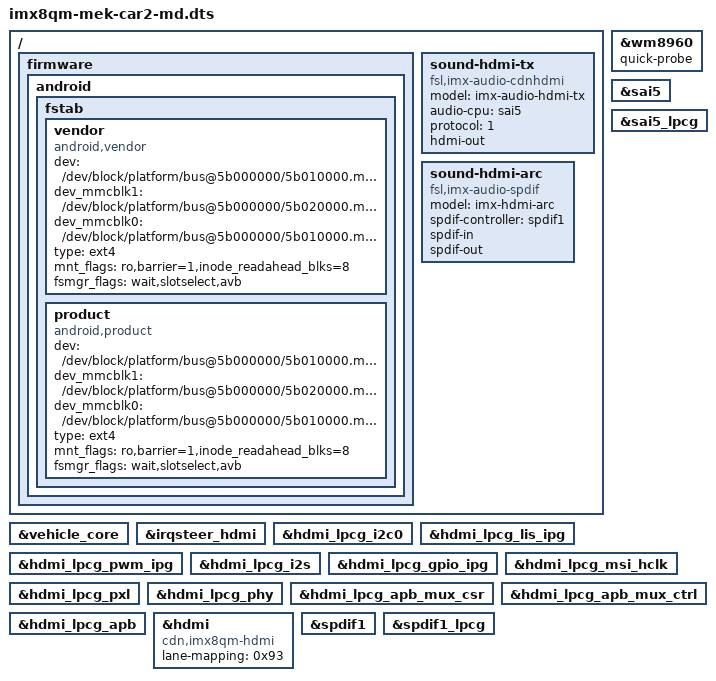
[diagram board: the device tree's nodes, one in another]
/*
 * Copyright 2020 NXP
 *
 * This program is free software; you can redistribute it and/or
 * modify it under the terms of the GNU General Public License
 * as published by the Free Software Foundation; either version 2
 * of the License, or (at your option) any later version.
 *
 * This program is distributed in the hope that it will be useful,
 * but WITHOUT ANY WARRANTY; without even the implied warranty of
 * MERCHANTABILITY or FITNESS FOR A PARTICULAR PURPOSE.  See the
 * GNU General Public License for more details.
 */

#include "imx8qm-mek-rpmsg.dts"

&wm8960 {
	quick-probe;
};

&vehicle_core {
	status = "okay";
};

/ {
	firmware {
		android {
			fstab {
				/delete-node/ system;
				vendor {
					compatible = "android,vendor";
					/* default emmc node used for GSI */
					dev = "/dev/block/platform/bus@5b000000/5b010000.mmc/by-name/vendor";
					/* sd card node which used if androidboot.boot_device_root=mmcblk1 */
					dev_mmcblk1 = "/dev/block/platform/bus@5b000000/5b020000.mmc/by-name/vendor";
					/* emmc node which used if androidboot.boot_device_root=mmcblk0 */
					dev_mmcblk0 = "/dev/block/platform/bus@5b000000/5b010000.mmc/by-name/vendor";
					type = "ext4";
					mnt_flags = "ro,barrier=1,inode_readahead_blks=8";
					fsmgr_flags = "wait,slotselect,avb";
				};
				product {
					compatible = "android,product";
					/* default emmc node used for GSI */
					dev = "/dev/block/platform/bus@5b000000/5b010000.mmc/by-name/product";
					/* sd card node which used if androidboot.boot_device_root=mmcblk1 */
					dev_mmcblk1 = "/dev/block/platform/bus@5b000000/5b020000.mmc/by-name/product";
					/* emmc node which used if androidboot.boot_device_root=mmcblk0 */
					dev_mmcblk0 = "/dev/block/platform/bus@5b000000/5b010000.mmc/by-name/product";
					type = "ext4";
					mnt_flags = "ro,barrier=1,inode_readahead_blks=8";
					fsmgr_flags = "wait,slotselect,avb";
				};
			};
		};
	};
};

/ {
    sound-hdmi-tx {
        compatible = "fsl,imx-audio-cdnhdmi";
        model = "imx-audio-hdmi-tx";
        audio-cpu = <&sai5>;
        protocol = <1>;
        hdmi-out;
    };

	sound-hdmi-arc {
		compatible = "fsl,imx-audio-spdif";
		model = "imx-hdmi-arc";
		spdif-controller = <&spdif1>;
		spdif-in;
		spdif-out;
	};
};

&sai5 {
	status = "okay";
};

&sai5_lpcg {
	status = "okay";
};

&irqsteer_hdmi {
	status = "okay";
};

&hdmi_lpcg_i2c0 {
	status = "okay";
};

&hdmi_lpcg_lis_ipg {
	status = "okay";
};

&hdmi_lpcg_pwm_ipg {
	status = "okay";
};

&hdmi_lpcg_i2s {
	status = "okay";
};

&hdmi_lpcg_gpio_ipg {
	status = "okay";
};

&hdmi_lpcg_msi_hclk {
	status = "okay";
};

&hdmi_lpcg_pxl {
	status = "okay";
};

&hdmi_lpcg_phy {
	status = "okay";
};

&hdmi_lpcg_apb_mux_csr {
	status = "okay";
};

&hdmi_lpcg_apb_mux_ctrl {
	status = "okay";
};

&hdmi_lpcg_apb {
	status = "okay";
};

&hdmi {
	compatible = "cdn,imx8qm-hdmi";
	lane-mapping = <0x93>;
	status = "okay";
};

&spdif1 {
	status = "okay";
};

&spdif1_lpcg {
	status = "okay";
};
